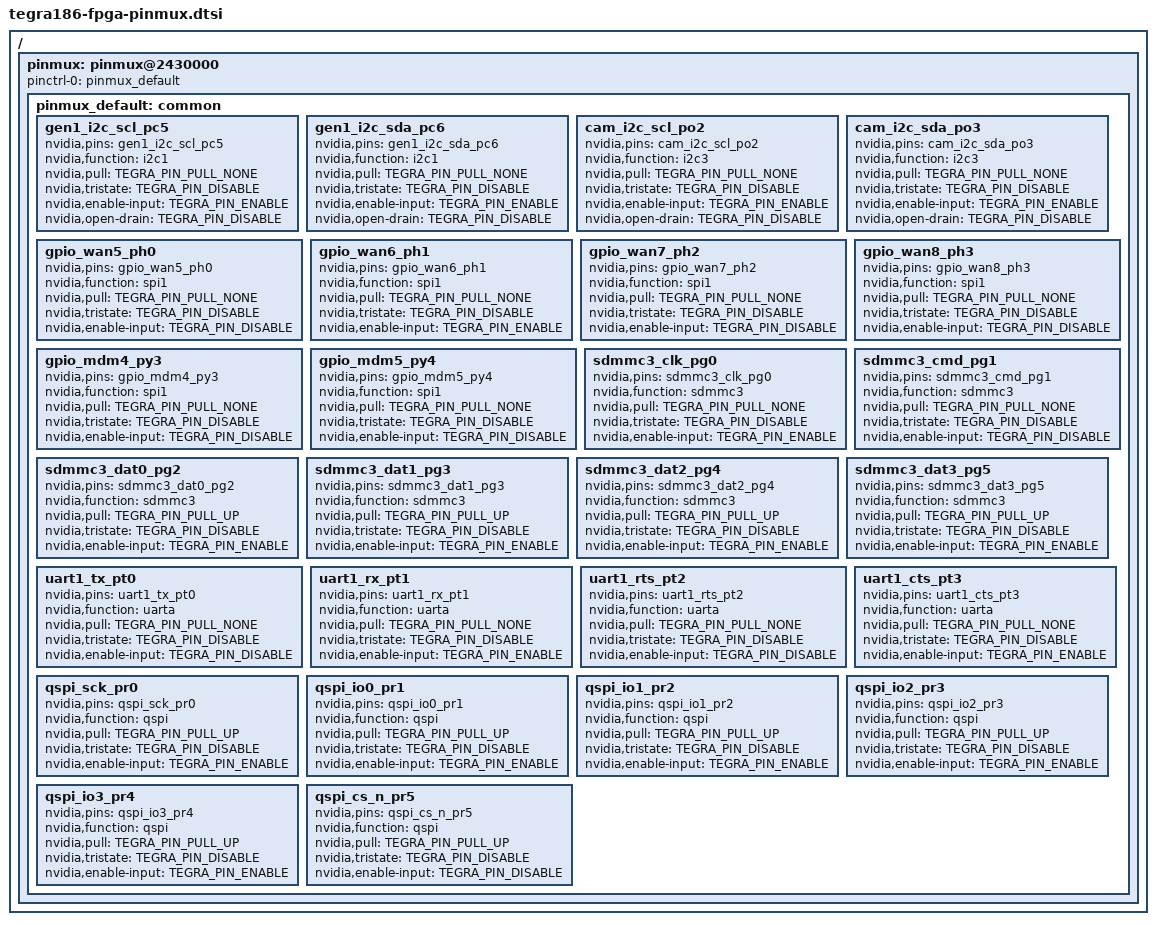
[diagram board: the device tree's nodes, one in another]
/*
 * Copyright (c) 2015, NVIDIA CORPORATION.  All rights reserved.
 *
 * This program is free software; you can redistribute it and/or modify
 * it under the terms of the GNU General Public License as published by
 * the Free Software Foundation; either version 2 of the License, or
 * (at your option) any later version.
 *
 * This program is distributed in the hope that it will be useful, but WITHOUT
 * ANY WARRANTY; without even the implied warranty of MERCHANTABILITY or
 * FITNESS FOR A PARTICULAR PURPOSE.  See the GNU General Public License for
 * more details.
 *
 * You should have received a copy of the GNU General Public License along
 * with this program; if not, write to the Free Software Foundation, Inc.,
 * 51 Franklin Street, Fifth Floor, Boston, MA  02110-1301, USA.
 */

#include <dt-bindings/pinctrl/pinctrl-tegra.h>

/ {

	pinmux: pinmux@2430000 {
		status = "okay";
		pinctrl-names = "default";
		pinctrl-0 = <&pinmux_default>;

		pinmux_default: common {
		/* SFIO Pin Configuration */
			gen1_i2c_scl_pc5 {
				nvidia,pins = "gen1_i2c_scl_pc5";
				nvidia,function = "i2c1";
				nvidia,pull = <TEGRA_PIN_PULL_NONE>;
				nvidia,tristate = <TEGRA_PIN_DISABLE>;
				nvidia,enable-input = <TEGRA_PIN_ENABLE>;
				nvidia,open-drain = <TEGRA_PIN_DISABLE>;
			};
			gen1_i2c_sda_pc6 {
				nvidia,pins = "gen1_i2c_sda_pc6";
				nvidia,function = "i2c1";
				nvidia,pull = <TEGRA_PIN_PULL_NONE>;
				nvidia,tristate = <TEGRA_PIN_DISABLE>;
				nvidia,enable-input = <TEGRA_PIN_ENABLE>;
				nvidia,open-drain = <TEGRA_PIN_DISABLE>;
			};
			cam_i2c_scl_po2 {
				nvidia,pins = "cam_i2c_scl_po2";
				nvidia,function = "i2c3";
				nvidia,pull = <TEGRA_PIN_PULL_NONE>;
				nvidia,tristate = <TEGRA_PIN_DISABLE>;
				nvidia,enable-input = <TEGRA_PIN_ENABLE>;
				nvidia,open-drain = <TEGRA_PIN_DISABLE>;
			};
			cam_i2c_sda_po3 {
				nvidia,pins = "cam_i2c_sda_po3";
				nvidia,function = "i2c3";
				nvidia,pull = <TEGRA_PIN_PULL_NONE>;
				nvidia,tristate = <TEGRA_PIN_DISABLE>;
				nvidia,enable-input = <TEGRA_PIN_ENABLE>;
				nvidia,open-drain = <TEGRA_PIN_DISABLE>;
			};
			gpio_wan5_ph0 {
				nvidia,pins = "gpio_wan5_ph0";
				nvidia,function = "spi1";
				nvidia,pull = <TEGRA_PIN_PULL_NONE>;
				nvidia,tristate = <TEGRA_PIN_DISABLE>;
				nvidia,enable-input = <TEGRA_PIN_DISABLE>;
			};
			gpio_wan6_ph1 {
				nvidia,pins = "gpio_wan6_ph1";
				nvidia,function = "spi1";
				nvidia,pull = <TEGRA_PIN_PULL_NONE>;
				nvidia,tristate = <TEGRA_PIN_DISABLE>;
				nvidia,enable-input = <TEGRA_PIN_ENABLE>;
			};
			gpio_wan7_ph2 {
				nvidia,pins = "gpio_wan7_ph2";
				nvidia,function = "spi1";
				nvidia,pull = <TEGRA_PIN_PULL_NONE>;
				nvidia,tristate = <TEGRA_PIN_DISABLE>;
				nvidia,enable-input = <TEGRA_PIN_DISABLE>;
			};
			gpio_wan8_ph3 {
				nvidia,pins = "gpio_wan8_ph3";
				nvidia,function = "spi1";
				nvidia,pull = <TEGRA_PIN_PULL_NONE>;
				nvidia,tristate = <TEGRA_PIN_DISABLE>;
				nvidia,enable-input = <TEGRA_PIN_DISABLE>;
			};
			gpio_mdm4_py3 {
				nvidia,pins = "gpio_mdm4_py3";
				nvidia,function = "spi1";
				nvidia,pull = <TEGRA_PIN_PULL_NONE>;
				nvidia,tristate = <TEGRA_PIN_DISABLE>;
				nvidia,enable-input = <TEGRA_PIN_DISABLE>;
			};
			gpio_mdm5_py4 {
				nvidia,pins = "gpio_mdm5_py4";
				nvidia,function = "spi1";
				nvidia,pull = <TEGRA_PIN_PULL_NONE>;
				nvidia,tristate = <TEGRA_PIN_DISABLE>;
				nvidia,enable-input = <TEGRA_PIN_DISABLE>;
			};

			sdmmc3_clk_pg0 {
				nvidia,pins = "sdmmc3_clk_pg0";
				nvidia,function = "sdmmc3";
				nvidia,pull = <TEGRA_PIN_PULL_NONE>;
				nvidia,tristate = <TEGRA_PIN_DISABLE>;
				nvidia,enable-input = <TEGRA_PIN_ENABLE>;
			};

			sdmmc3_cmd_pg1 {
				nvidia,pins = "sdmmc3_cmd_pg1";
				nvidia,function = "sdmmc3";
				nvidia,pull = <TEGRA_PIN_PULL_NONE>;
				nvidia,tristate = <TEGRA_PIN_DISABLE>;
				nvidia,enable-input = <TEGRA_PIN_DISABLE>;
			};

			sdmmc3_dat0_pg2 {
				nvidia,pins = "sdmmc3_dat0_pg2";
				nvidia,function = "sdmmc3";
				nvidia,pull = <TEGRA_PIN_PULL_UP>;
				nvidia,tristate = <TEGRA_PIN_DISABLE>;
				nvidia,enable-input = <TEGRA_PIN_ENABLE>;
			};

			sdmmc3_dat1_pg3 {
				nvidia,pins = "sdmmc3_dat1_pg3";
				nvidia,function = "sdmmc3";
				nvidia,pull = <TEGRA_PIN_PULL_UP>;
				nvidia,tristate = <TEGRA_PIN_DISABLE>;
				nvidia,enable-input = <TEGRA_PIN_ENABLE>;
			};

			sdmmc3_dat2_pg4 {
				nvidia,pins = "sdmmc3_dat2_pg4";
				nvidia,function = "sdmmc3";
				nvidia,pull = <TEGRA_PIN_PULL_UP>;
				nvidia,tristate = <TEGRA_PIN_DISABLE>;
				nvidia,enable-input = <TEGRA_PIN_ENABLE>;
			};

			sdmmc3_dat3_pg5 {
				nvidia,pins = "sdmmc3_dat3_pg5";
				nvidia,function = "sdmmc3";
				nvidia,pull = <TEGRA_PIN_PULL_UP>;
				nvidia,tristate = <TEGRA_PIN_DISABLE>;
				nvidia,enable-input = <TEGRA_PIN_ENABLE>;
			};

			uart1_tx_pt0 {
				nvidia,pins = "uart1_tx_pt0";
				nvidia,function = "uarta";
				nvidia,pull = <TEGRA_PIN_PULL_NONE>;
				nvidia,tristate = <TEGRA_PIN_DISABLE>;
				nvidia,enable-input = <TEGRA_PIN_DISABLE>;
			};

			uart1_rx_pt1 {
				nvidia,pins = "uart1_rx_pt1";
				nvidia,function = "uarta";
				nvidia,pull = <TEGRA_PIN_PULL_NONE>;
				nvidia,tristate = <TEGRA_PIN_DISABLE>;
				nvidia,enable-input = <TEGRA_PIN_ENABLE>;
			};

			uart1_rts_pt2 {
				nvidia,pins = "uart1_rts_pt2";
				nvidia,function = "uarta";
				nvidia,pull = <TEGRA_PIN_PULL_NONE>;
				nvidia,tristate = <TEGRA_PIN_DISABLE>;
				nvidia,enable-input = <TEGRA_PIN_DISABLE>;
			};

			uart1_cts_pt3 {
				nvidia,pins = "uart1_cts_pt3";
				nvidia,function = "uarta";
				nvidia,pull = <TEGRA_PIN_PULL_NONE>;
				nvidia,tristate = <TEGRA_PIN_DISABLE>;
				nvidia,enable-input = <TEGRA_PIN_ENABLE>;
			};
			qspi_sck_pr0 {
				nvidia,pins = "qspi_sck_pr0";
				nvidia,function = "qspi";
				nvidia,pull = <TEGRA_PIN_PULL_UP>;
				nvidia,tristate = <TEGRA_PIN_DISABLE>;
				nvidia,enable-input = <TEGRA_PIN_ENABLE>;
			};
			qspi_io0_pr1 {
				nvidia,pins = "qspi_io0_pr1";
				nvidia,function = "qspi";
				nvidia,pull = <TEGRA_PIN_PULL_UP>;
				nvidia,tristate = <TEGRA_PIN_DISABLE>;
				nvidia,enable-input = <TEGRA_PIN_ENABLE>;
			};
			qspi_io1_pr2 {
				nvidia,pins = "qspi_io1_pr2";
				nvidia,function = "qspi";
				nvidia,pull = <TEGRA_PIN_PULL_UP>;
				nvidia,tristate = <TEGRA_PIN_DISABLE>;
				nvidia,enable-input = <TEGRA_PIN_ENABLE>;
			};
			qspi_io2_pr3 {
				nvidia,pins = "qspi_io2_pr3";
				nvidia,function = "qspi";
				nvidia,pull = <TEGRA_PIN_PULL_UP>;
				nvidia,tristate = <TEGRA_PIN_DISABLE>;
				nvidia,enable-input = <TEGRA_PIN_ENABLE>;
			};
			qspi_io3_pr4 {
				nvidia,pins = "qspi_io3_pr4";
				nvidia,function = "qspi";
				nvidia,pull = <TEGRA_PIN_PULL_UP>;
				nvidia,tristate = <TEGRA_PIN_DISABLE>;
				nvidia,enable-input = <TEGRA_PIN_ENABLE>;
			};
			qspi_cs_n_pr5 {
				nvidia,pins = "qspi_cs_n_pr5";
				nvidia,function = "qspi";
				nvidia,pull = <TEGRA_PIN_PULL_UP>;
				nvidia,tristate = <TEGRA_PIN_DISABLE>;
				nvidia,enable-input = <TEGRA_PIN_DISABLE>;
			};
		};
	};
};
